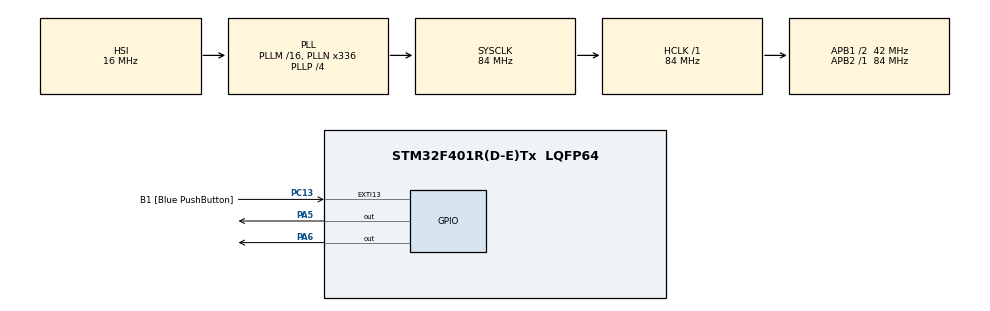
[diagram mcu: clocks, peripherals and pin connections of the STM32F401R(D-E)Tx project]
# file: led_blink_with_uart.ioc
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FREERTOS.BinarySemaphores01=myBinarySem01,Dynamic,NULL
FREERTOS.Tasks01=defaultTask,0,128,StartDefaultTask,Default,NULL,Dynamic,NULL,NULL;myTask02,-2,128,StartTask02,Default,NULL,Dynamic,NULL,NULL;myTask03,-2,128,StartTask03,Default,NULL,Dynamic,NULL,NULL
FREERTOS.configTOTAL_HEAP_SIZE=32720
FREERTOS.configUSE_NEWLIB_REENTRANT=1
Mcu.Family=STM32F4
Mcu.Name=STM32F401R(D-E)Tx
Mcu.Package=LQFP64
NVIC.PriorityGroup=NVIC_PRIORITYGROUP_4
NVIC.TIM1_UP_TIM10_IRQn=true\:15\:0\:false\:false\:true\:false\:false\:true
NVIC.TimeBase=TIM1_UP_TIM10_IRQn
NVIC.TimeBaseIP=TIM1
PA13.GPIO_Label=TMS
PA13.Mode=Serial_Wire
PA13.Signal=SYS_JTMS-SWDIO
PA14.GPIO_Label=TCK
PA14.Mode=Serial_Wire
PA14.Signal=SYS_JTCK-SWCLK
PA5.Signal=GPIO_Output
PA6.Signal=GPIO_Output
PB3.GPIO_Label=SWO
PB3.Signal=SYS_JTDO-SWO
PC13-ANTI_TAMP.GPIO_Label=B1 [Blue PushButton]
PC13-ANTI_TAMP.GPIO_ModeDefaultEXTI=GPIO_MODE_IT_FALLING
PC13-ANTI_TAMP.GPIO_PuPd=GPIO_NOPULL
PC13-ANTI_TAMP.Signal=GPXTI13
PC14-OSC32_IN.Signal=RCC_OSC32_IN
PC15-OSC32_OUT.Signal=RCC_OSC32_OUT
PH0\ -\ OSC_IN.Mode=HSE-External-Oscillator
PH0\ -\ OSC_IN.Signal=RCC_OSC_IN
PH1\ -\ OSC_OUT.Mode=HSE-External-Oscillator
PH1\ -\ OSC_OUT.Signal=RCC_OSC_OUT
ProjectManager.HeapSize=0x200
ProjectManager.StackSize=0x400
ProjectManager.TargetToolchain=STM32CubeIDE
RCC.48MHZClocksFreq_Value=48000000
RCC.AHBFreq_Value=84000000
RCC.APB1CLKDivider=RCC_HCLK_DIV2
RCC.APB1Freq_Value=42000000
RCC.APB1TimFreq_Value=84000000
RCC.APB2Freq_Value=84000000
RCC.APB2TimFreq_Value=84000000
RCC.CortexFreq_Value=84000000
RCC.HCLKFreq_Value=84000000
RCC.HSE_VALUE=8000000
RCC.HSI_VALUE=16000000
RCC.LSE_VALUE=32768
RCC.PLLN=336
RCC.PLLP=RCC_PLLP_DIV4
RCC.PLLQ=7
RCC.SYSCLKFreq_VALUE=84000000
RCC.SYSCLKSource=RCC_SYSCLKSOURCE_PLLCLK
RCC.VCOOutputFreq_Value=336000000
VP_FREERTOS_VS_CMSIS_V1.Mode=CMSIS_V1
VP_SYS_VS_tim1.Mode=TIM1
board=NUCLEO-F401RE

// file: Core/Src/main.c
/* USER CODE BEGIN Header */
/**
  ******************************************************************************
  * @file           : main.c
  * @brief          : Main program body
  ******************************************************************************
  * @attention
  *
  * <h2><center>&copy; Copyright (c) 2022 STMicroelectronics.
  * All rights reserved.</center></h2>
  *
  * This software component is licensed by ST under BSD 3-Clause license,
  * the "License"; You may not use this file except in compliance with the
  * License. You may obtain a copy of the License at:
  *                        opensource.org/licenses/BSD-3-Clause
  *
  ******************************************************************************
  */
/* USER CODE END Header */
#include "main.h"
#include "cmsis_os.h"

/* USER CODE BEGIN Includes */
#include <string.h>
#include <stdio.h>
#include <stdint.h>
/* USER CODE END Includes */

/* USER CODE BEGIN PD */
#define LED1
#define LED1_LINE GPIOA
#define LED1_PIN GPIO_PIN_5
#define LED2_LINE GPIOA
#define LED2_PIN GPIO_PIN_6
#define FREQ 500 //ms
/* USER CODE END PD */

osThreadId defaultTaskHandle;
osThreadId myTask02Handle;
osThreadId myTask03Handle;
osSemaphoreId myBinarySem01Handle;
/* USER CODE BEGIN PV */
volatile uint8_t btn_flag = 1;
uint32_t btn_time = 0;
volatile uint8_t led_status = 1;
/* USER CODE END PV */

void SystemClock_Config(void);
static void MX_GPIO_Init(void);
void StartDefaultTask(void const * argument);
void StartTask02(void const * argument);
void StartTask03(void const * argument);

/* USER CODE BEGIN PFP */
void led(volatile uint8_t control);
/* USER CODE END PFP */

int main(void)
{

  /* MCU Configuration--------------------------------------------------------*/

  /* Reset of all peripherals, Initializes the Flash interface and the Systick. */
  HAL_Init();

  /* Configure the system clock */
  SystemClock_Config();

  /* Initialize all configured peripherals */
  MX_GPIO_Init();

  /* Create the semaphores(s) */
  /* definition and creation of myBinarySem01 */
  osSemaphoreDef(myBinarySem01);
  myBinarySem01Handle = osSemaphoreCreate(osSemaphore(myBinarySem01), 1);

  /* Create the thread(s) */
  /* definition and creation of defaultTask */
  osThreadDef(defaultTask, StartDefaultTask, osPriorityNormal, 0, 128);
  defaultTaskHandle = osThreadCreate(osThread(defaultTask), NULL);

  /* definition and creation of myTask02 */
  osThreadDef(myTask02, StartTask02, osPriorityLow, 0, 128);
  myTask02Handle = osThreadCreate(osThread(myTask02), NULL);

  /* definition and creation of myTask03 */
  osThreadDef(myTask03, StartTask03, osPriorityLow, 0, 128);
  myTask03Handle = osThreadCreate(osThread(myTask03), NULL);

  /* Start scheduler */
  osKernelStart();

  /* We should never get here as control is now taken by the scheduler */
  /* Infinite loop */
  while (1)
  {

  }
}

void SystemClock_Config(void)
{
  RCC_OscInitTypeDef RCC_OscInitStruct = {0};
  RCC_ClkInitTypeDef RCC_ClkInitStruct = {0};

  /** Configure the main internal regulator output voltage
  */
  __HAL_RCC_PWR_CLK_ENABLE();
  __HAL_PWR_VOLTAGESCALING_CONFIG(PWR_REGULATOR_VOLTAGE_SCALE2);
  /** Initializes the RCC Oscillators according to the specified parameters
  * in the RCC_OscInitTypeDef structure.
  */
  RCC_OscInitStruct.OscillatorType = RCC_OSCILLATORTYPE_HSI;
  RCC_OscInitStruct.HSIState = RCC_HSI_ON;
  RCC_OscInitStruct.HSICalibrationValue = RCC_HSICALIBRATION_DEFAULT;
  RCC_OscInitStruct.PLL.PLLState = RCC_PLL_ON;
  RCC_OscInitStruct.PLL.PLLSource = RCC_PLLSOURCE_HSI;
  RCC_OscInitStruct.PLL.PLLM = 16;
  RCC_OscInitStruct.PLL.PLLN = 336;
  RCC_OscInitStruct.PLL.PLLP = RCC_PLLP_DIV4;
  RCC_OscInitStruct.PLL.PLLQ = 7;
  if (HAL_RCC_OscConfig(&RCC_OscInitStruct) != HAL_OK)
  {
    Error_Handler();
  }
  /** Initializes the CPU, AHB and APB buses clocks
  */
  RCC_ClkInitStruct.ClockType = RCC_CLOCKTYPE_HCLK|RCC_CLOCKTYPE_SYSCLK
                              |RCC_CLOCKTYPE_PCLK1|RCC_CLOCKTYPE_PCLK2;
  RCC_ClkInitStruct.SYSCLKSource = RCC_SYSCLKSOURCE_PLLCLK;
  RCC_ClkInitStruct.AHBCLKDivider = RCC_SYSCLK_DIV1;
  RCC_ClkInitStruct.APB1CLKDivider = RCC_HCLK_DIV2;
  RCC_ClkInitStruct.APB2CLKDivider = RCC_HCLK_DIV1;

  if (HAL_RCC_ClockConfig(&RCC_ClkInitStruct, FLASH_LATENCY_2) != HAL_OK)
  {
    Error_Handler();
  }
}

static void MX_GPIO_Init(void)
{
  GPIO_InitTypeDef GPIO_InitStruct = {0};

  /* GPIO Ports Clock Enable */
  __HAL_RCC_GPIOC_CLK_ENABLE();
  __HAL_RCC_GPIOH_CLK_ENABLE();
  __HAL_RCC_GPIOA_CLK_ENABLE();
  __HAL_RCC_GPIOB_CLK_ENABLE();

  /*Configure GPIO pin Output Level */
  HAL_GPIO_WritePin(GPIOA, GPIO_PIN_5|GPIO_PIN_6, GPIO_PIN_RESET);

  /*Configure GPIO pin : B1_Pin */
  GPIO_InitStruct.Pin = B1_Pin;
  GPIO_InitStruct.Mode = GPIO_MODE_IT_FALLING;
  GPIO_InitStruct.Pull = GPIO_NOPULL;
  HAL_GPIO_Init(B1_GPIO_Port, &GPIO_InitStruct);

  /*Configure GPIO pins : PA5 PA6 */
  GPIO_InitStruct.Pin = GPIO_PIN_5|GPIO_PIN_6;
  GPIO_InitStruct.Mode = GPIO_MODE_OUTPUT_PP;
  GPIO_InitStruct.Pull = GPIO_NOPULL;
  GPIO_InitStruct.Speed = GPIO_SPEED_FREQ_LOW;
  HAL_GPIO_Init(GPIOA, &GPIO_InitStruct);

}

/* USER CODE BEGIN 4 */
void led(volatile uint8_t control) {
	if(control == 1) {
#ifdef LED1
	  HAL_GPIO_TogglePin(LED1_LINE, LED1_PIN);
#endif
#ifdef LED2
	  HAL_GPIO_TogglePin(LED2_LINE, LED2_PIN);
#endif
	  HAL_Delay(FREQ);
	}
}

void TaskHandler(uint8_t ID_Task) {
	if(myBinarySem01Handle != NULL) {
		if(osSemaphoreWait(myBinarySem01Handle, 100) == osOK) {
			if(ID_Task == 1) {
				led(led_status);
			}
			if(ID_Task == 2) {
				if(HAL_GPIO_ReadPin(B1_GPIO_Port, B1_Pin) == GPIO_PIN_RESET && btn_flag) {
				btn_flag = 0;
				// action by pressing
				if(led_status == 1) {
					led_status = 0;
				} else {
					led_status = 1;
				}
				btn_time = HAL_GetTick();
			  }
			}
			if(ID_Task == 3) {
				if(!btn_flag && (HAL_GetTick() - btn_time) > 500) {
					btn_flag = 1;
				}
			}
			osSemaphoreRelease(myBinarySem01Handle);
		}
	}
}
/* USER CODE END 4 */

void StartDefaultTask(void const * argument)
{
  /* USER CODE BEGIN 5 */
  /* Infinite loop */
  for(;;)
  {
	TaskHandler(1);
    osDelay(1);
  }
  /* USER CODE END 5 */
}

void StartTask02(void const * argument)
{
  /* USER CODE BEGIN StartTask02 */
  /* Infinite loop */
  for(;;)
  {
	TaskHandler(2);
    osDelay(1);
  }
  /* USER CODE END StartTask02 */
}

void StartTask03(void const * argument)
{
  /* USER CODE BEGIN StartTask03 */
  /* Infinite loop */
  for(;;)
  {
	TaskHandler(3);
    osDelay(1);
  }
  /* USER CODE END StartTask03 */
}

void HAL_TIM_PeriodElapsedCallback(TIM_HandleTypeDef *htim)
{
  if (htim->Instance == TIM1) {
    HAL_IncTick();
  }
}

void Error_Handler(void)
{
  __disable_irq();
  while (1)
  {
  }
}

/************************ (C) COPYRIGHT STMicroelectronics *****END OF FILE****/
